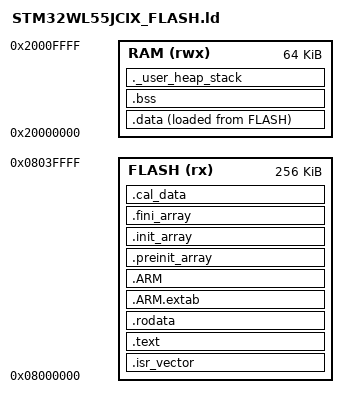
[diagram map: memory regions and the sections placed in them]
/* Soil Whisper — STM32WL55JC Linker Script
 * 256 KB Flash, 64 KB RAM
 */

MEMORY
{
  FLASH (rx)  : ORIGIN = 0x08000000, LENGTH = 256K
  RAM (rwx)   : ORIGIN = 0x20000000, LENGTH = 64K
}

/* Stack and heap sizes */
STACK_SIZE = 0x400;   /* 1 KB */
HEAP_SIZE  = 0x200;   /* 512 B */

SECTIONS
{
  .isr_vector :
  {
    . = ALIGN(4);
    KEEP(*(.isr_vector))
    . = ALIGN(4);
  } > FLASH

  .text :
  {
    . = ALIGN(4);
    *(.text)
    *(.text*)
    *(.glue_7)
    *(.glue_7t)
    KEEP(*(.init))
    KEEP(*(.fini))
    . = ALIGN(4);
    _etext = .;
  } > FLASH

  .rodata :
  {
    . = ALIGN(4);
    *(.rodata)
    *(.rodata*)
    . = ALIGN(4);
  } > FLASH

  .ARM.extab :
  {
    *(.ARM.extab* .gnu.linkonce.armextab.*)
  } > FLASH

  .ARM :
  {
    __exidx_start = .;
    *(.ARM.exidx*)
    __exidx_end = .;
  } > FLASH

  .preinit_array :
  {
    PROVIDE_HIDDEN(__preinit_array_start = .);
    KEEP(*(.preinit_array*))
    PROVIDE_HIDDEN(__preinit_array_end = .);
  } > FLASH

  .init_array :
  {
    PROVIDE_HIDDEN(__init_array_start = .);
    KEEP(*(SORT(.init_array.*)))
    KEEP(*(.init_array*))
    PROVIDE_HIDDEN(__init_array_end = .);
  } > FLASH

  .fini_array :
  {
    PROVIDE_HIDDEN(__fini_array_start = .);
    KEEP(*(SORT(.fini_array.*)))
    KEEP(*(.fini_array*))
    PROVIDE_HIDDEN(__fini_array_end = .);
  } > FLASH

  _sidata = LOADADDR(.data);

  .data :
  {
    . = ALIGN(4);
    _sdata = .;
    *(.data)
    *(.data*)
    . = ALIGN(4);
    _edata = .;
  } > RAM AT > FLASH

  .bss :
  {
    . = ALIGN(4);
    _sbss = .;
    __bss_start__ = _sbss;
    *(.bss)
    *(.bss*)
    *(COMMON)
    . = ALIGN(4);
    _ebss = .;
    __bss_end__ = _ebss;
  } > RAM

  /* User heap stack */
  ._user_heap_stack :
  {
    . = ALIGN(8);
    PROVIDE(end = .);
    PROVIDE(_end = .);
    . = . + HEAP_SIZE;
    . = . + STACK_SIZE;
    . = ALIGN(8);
  } > RAM

  /* Remove debug sections */
  /DISCARD/ :
  {
    *(.ARM.attributes)
    *(.comment)
    *(.debug*)
  }

  /* Calibration data stored in last flash page */
  .cal_data (NOLOAD) :
  {
    . = ALIGN(4);
    __cal_data_start = .;
    . = . + 2048;  /* 2 KB for calibration data */
    __cal_data_end = .;
  } > FLASH
}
